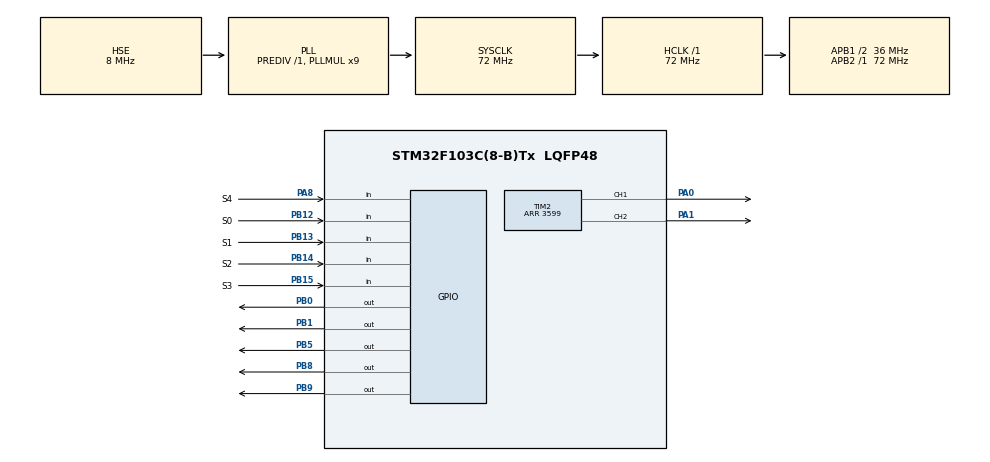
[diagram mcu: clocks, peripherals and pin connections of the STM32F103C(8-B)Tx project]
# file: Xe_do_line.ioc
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Mcu.Family=STM32F1
Mcu.Name=STM32F103C(8-B)Tx
Mcu.Package=LQFP48
NVIC.PriorityGroup=NVIC_PRIORITYGROUP_4
NVIC.TIM1_UP_IRQn=true\:1\:0\:true\:false\:true\:true\:true\:true
PA0-WKUP.Signal=S_TIM2_CH1_ETR
PA1.Signal=S_TIM2_CH2
PA13.Mode=Serial_Wire
PA13.Signal=SYS_JTMS-SWDIO
PA14.Mode=Serial_Wire
PA14.Signal=SYS_JTCK-SWCLK
PA8.GPIO_Label=S4
PA8.Signal=GPIO_Input
PB0.Signal=GPIO_Output
PB1.Signal=GPIO_Output
PB12.GPIO_Label=S0
PB12.Signal=GPIO_Input
PB13.GPIO_Label=S1
PB13.Signal=GPIO_Input
PB14.GPIO_Label=S2
PB14.Signal=GPIO_Input
PB15.GPIO_Label=S3
PB15.Signal=GPIO_Input
PB5.Signal=GPIO_Output
PB8.Signal=GPIO_Output
PB9.Signal=GPIO_Output
PC14-OSC32_IN.Mode=LSE-External-Oscillator
PC14-OSC32_IN.Signal=RCC_OSC32_IN
PC15-OSC32_OUT.Mode=LSE-External-Oscillator
PC15-OSC32_OUT.Signal=RCC_OSC32_OUT
PD0-OSC_IN.Mode=HSE-External-Oscillator
PD0-OSC_IN.Signal=RCC_OSC_IN
PD1-OSC_OUT.Mode=HSE-External-Oscillator
PD1-OSC_OUT.Signal=RCC_OSC_OUT
ProjectManager.HeapSize=0x200
ProjectManager.StackSize=0x400
ProjectManager.TargetToolchain=STM32CubeIDE
RCC.AHBFreq_Value=72000000
RCC.APB1CLKDivider=RCC_HCLK_DIV2
RCC.APB1Freq_Value=36000000
RCC.APB1TimFreq_Value=72000000
RCC.APB2Freq_Value=72000000
RCC.APB2TimFreq_Value=72000000
RCC.HCLKFreq_Value=72000000
RCC.PLLMUL=RCC_PLL_MUL9
RCC.PLLSourceVirtual=RCC_PLLSOURCE_HSE
RCC.SYSCLKFreq_VALUE=72000000
RCC.SYSCLKSource=RCC_SYSCLKSOURCE_PLLCLK
RCC.USBFreq_Value=72000000
SH.S_TIM2_CH1_ETR.0=TIM2_CH1,PWM Generation1 CH1
SH.S_TIM2_CH2.0=TIM2_CH2,PWM Generation2 CH2
TIM1.Period=49
TIM1.Prescaler=7199
TIM2.Channel-PWM\ Generation1\ CH1=TIM_CHANNEL_1
TIM2.Channel-PWM\ Generation2\ CH2=TIM_CHANNEL_2
TIM2.Period=3599
VP_TIM1_VS_ClockSourceINT.Mode=Internal
VP_TIM2_VS_ClockSourceINT.Mode=Internal
board=custom

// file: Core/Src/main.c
/* USER CODE BEGIN Header */
/**
  ******************************************************************************
  * @file           : main.c
  * @brief          : STM32F103 Line Following Robot
  ******************************************************************************
  * @attention
  *
  * Copyright (c) 2026 STMicroelectronics.
  * All rights reserved.
  *
  * This software is licensed under terms that can be found in the LICENSE file
  * in the root directory of this software component.
  * If no LICENSE file comes with this software, it is provided AS-IS.
  *
  ******************************************************************************
  */
/* USER CODE END Header */

#include "main.h"
#include "tim.h"
#include "gpio.h"

/* USER CODE BEGIN Includes */
#include "control.h"
/* USER CODE END Includes */

void SystemClock_Config(void);

int main(void)
{

  /* Khoi tao HAL */
  HAL_Init();

  /* Cau hinh Clock */
  SystemClock_Config();

  /* Khoi tao ngoai vi */
  MX_GPIO_Init();
  MX_TIM1_Init();
  MX_TIM2_Init();

  /* USER CODE BEGIN 2 */
  Control_Init();

  HAL_Delay(3000);

  Control_Start();
  /* USER CODE END 2 */

  /* Infinite loop */
  while (1)
  {

    /* USER CODE BEGIN 3 */

    HAL_Delay(100);

    /* USER CODE END 3 */
  }
}

void SystemClock_Config(void)
{
  RCC_OscInitTypeDef RCC_OscInitStruct = {0};
  RCC_ClkInitTypeDef RCC_ClkInitStruct = {0};

  RCC_OscInitStruct.OscillatorType = RCC_OSCILLATORTYPE_HSE;
  RCC_OscInitStruct.HSEState = RCC_HSE_ON;
  RCC_OscInitStruct.HSEPredivValue = RCC_HSE_PREDIV_DIV1;
  RCC_OscInitStruct.HSIState = RCC_HSI_ON;
  RCC_OscInitStruct.PLL.PLLSource = RCC_PLLSOURCE_HSE;
  RCC_OscInitStruct.PLL.PLLMUL = RCC_PLL_MUL9;
  RCC_OscInitStruct.PLL.PLLState = RCC_PLL_ON;

  if (HAL_RCC_OscConfig(&RCC_OscInitStruct) != HAL_OK)
  {
    Error_Handler();
  }

  RCC_ClkInitStruct.ClockType =
      RCC_CLOCKTYPE_HCLK |
      RCC_CLOCKTYPE_SYSCLK |
      RCC_CLOCKTYPE_PCLK1 |
      RCC_CLOCKTYPE_PCLK2;

  RCC_ClkInitStruct.SYSCLKSource = RCC_SYSCLKSOURCE_PLLCLK;
  RCC_ClkInitStruct.AHBCLKDivider = RCC_SYSCLK_DIV1;
  RCC_ClkInitStruct.APB1CLKDivider = RCC_HCLK_DIV2;
  RCC_ClkInitStruct.APB2CLKDivider = RCC_HCLK_DIV1;

  if (HAL_RCC_ClockConfig(&RCC_ClkInitStruct,
                          FLASH_LATENCY_2) != HAL_OK)
  {
    Error_Handler();
  }
}

/**
  * @brief Error Handler
  * @retval None
  */
void Error_Handler(void)
{
  __disable_irq();
  while (1)
  {
  }
}

#ifdef USE_FULL_ASSERT

void assert_failed(uint8_t *file, uint32_t line)
{
  /* USER CODE BEGIN 6 */

  (void)file;
  (void)line;

  /* USER CODE END 6 */
}

#endif /* USE_FULL_ASSERT */
